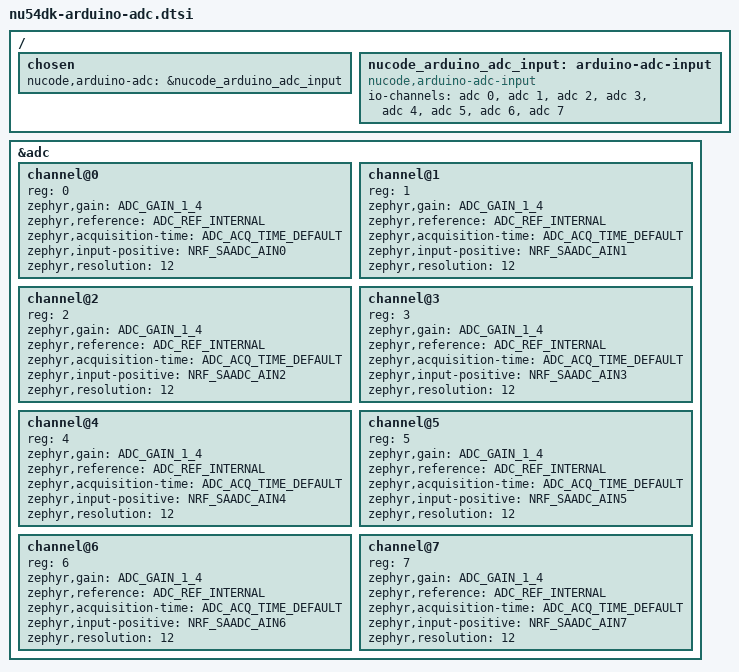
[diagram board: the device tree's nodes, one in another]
/**
 * @file nu54dk-arduino-adc.dtsi
 * @brief Arduino ADC chosen과 SAADC 여덟 channel만 활성화합니다.
 * SPDX-License-Identifier: MIT
 */

#include <zephyr/dt-bindings/adc/adc.h>
#include <zephyr/dt-bindings/adc/nrf-saadc.h>

/ {
	chosen {
		nucode,arduino-adc = &nucode_arduino_adc_input;
	};

	nucode_arduino_adc_input: arduino-adc-input {
		compatible = "nucode,arduino-adc-input";
		io-channels = <&adc 0>, <&adc 1>, <&adc 2>, <&adc 3>,
			<&adc 4>, <&adc 5>, <&adc 6>, <&adc 7>;
	};
};

&adc {
	#address-cells = <1>;
	#size-cells = <0>;
	status = "okay";

	channel@0 {
		reg = <0>;
		zephyr,gain = "ADC_GAIN_1_4";
		zephyr,reference = "ADC_REF_INTERNAL";
		zephyr,acquisition-time = <ADC_ACQ_TIME_DEFAULT>;
		zephyr,input-positive = <NRF_SAADC_AIN0>;
		zephyr,resolution = <12>;
	};
	channel@1 {
		reg = <1>;
		zephyr,gain = "ADC_GAIN_1_4";
		zephyr,reference = "ADC_REF_INTERNAL";
		zephyr,acquisition-time = <ADC_ACQ_TIME_DEFAULT>;
		zephyr,input-positive = <NRF_SAADC_AIN1>;
		zephyr,resolution = <12>;
	};
	channel@2 {
		reg = <2>;
		zephyr,gain = "ADC_GAIN_1_4";
		zephyr,reference = "ADC_REF_INTERNAL";
		zephyr,acquisition-time = <ADC_ACQ_TIME_DEFAULT>;
		zephyr,input-positive = <NRF_SAADC_AIN2>;
		zephyr,resolution = <12>;
	};
	channel@3 {
		reg = <3>;
		zephyr,gain = "ADC_GAIN_1_4";
		zephyr,reference = "ADC_REF_INTERNAL";
		zephyr,acquisition-time = <ADC_ACQ_TIME_DEFAULT>;
		zephyr,input-positive = <NRF_SAADC_AIN3>;
		zephyr,resolution = <12>;
	};
	channel@4 {
		reg = <4>;
		zephyr,gain = "ADC_GAIN_1_4";
		zephyr,reference = "ADC_REF_INTERNAL";
		zephyr,acquisition-time = <ADC_ACQ_TIME_DEFAULT>;
		zephyr,input-positive = <NRF_SAADC_AIN4>;
		zephyr,resolution = <12>;
	};
	channel@5 {
		reg = <5>;
		zephyr,gain = "ADC_GAIN_1_4";
		zephyr,reference = "ADC_REF_INTERNAL";
		zephyr,acquisition-time = <ADC_ACQ_TIME_DEFAULT>;
		zephyr,input-positive = <NRF_SAADC_AIN5>;
		zephyr,resolution = <12>;
	};
	channel@6 {
		reg = <6>;
		zephyr,gain = "ADC_GAIN_1_4";
		zephyr,reference = "ADC_REF_INTERNAL";
		zephyr,acquisition-time = <ADC_ACQ_TIME_DEFAULT>;
		zephyr,input-positive = <NRF_SAADC_AIN6>;
		zephyr,resolution = <12>;
	};
	channel@7 {
		reg = <7>;
		zephyr,gain = "ADC_GAIN_1_4";
		zephyr,reference = "ADC_REF_INTERNAL";
		zephyr,acquisition-time = <ADC_ACQ_TIME_DEFAULT>;
		zephyr,input-positive = <NRF_SAADC_AIN7>;
		zephyr,resolution = <12>;
	};
};
